# MDR32F8 register map
Vendor: Milandr; File version: 1.0
CPU: CM4 r1p1, little endian, no MPU, no FPU, 3 interrupt priority bits
Registers are 32-bit, read-write, reset 0x0 unless marked. A register's access mark holds for its fields unless they carry their own. Offsets are from the block's base; [hi:lo] are bit positions; {n}, {i} and the like mark numbered series; 'fields as' and 'values as' point back to an identical list.

## MDR_SPW — SPW controller
Base 0x40088000
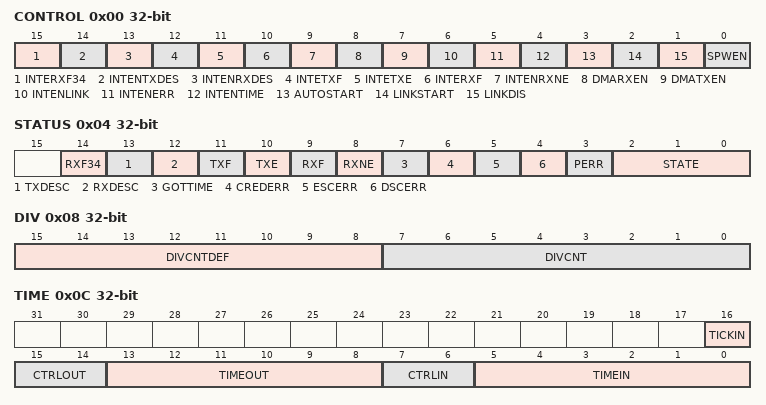
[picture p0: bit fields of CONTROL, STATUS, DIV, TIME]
0x00 CONTROL — SPW Control Register
  [15] INTERXF34, [14] INTENTXDES, [13] INTENRXDES, [12] INTETXF, [11] INTETXE, [10] INTERXF, [9] INTENRXNE, [8] DMARXEN, [7] DMATXEN, [6] INTENLINK, [5] INTENERR, [4] INTENTIME, [3] AUTOSTART, [2] LINKSTART, [1] LINKDIS, [0] SPWEN
0x04 STATUS — SPW Status Register
  [14] RXF34, [13] TXDESC, [12] RXDESC, [11] TXF, [10] TXE, [9] RXF, [8] RXNE, [7] GOTTIME, [6] CREDERR, [5] ESCERR, [4] DSCERR, [3] PERR, [2:0] STATE
0x08 DIV — DIV Configuration Register
  [15:8] DIVCNTDEF, [7:0] DIVCNT
0x0C TIME
  [16] TICKIN, [15:14] CTRLOUT, [13:8] TIMEOUT, [7:6] CTRLIN, [5:0] TIMEIN
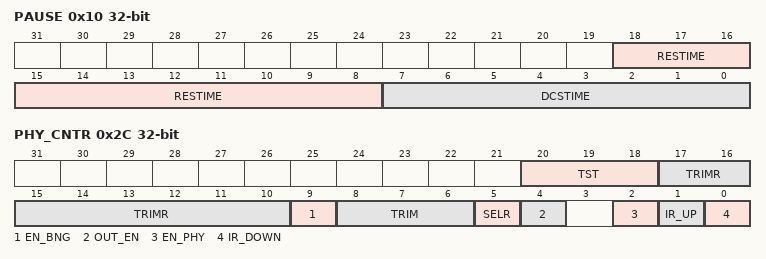
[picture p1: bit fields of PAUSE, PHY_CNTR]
0x10 PAUSE
  [18:8] RESTIME, [7:0] DCSTIME
0x14 FIFORX
  [31:0] DATA
0x18 FIFOTX
  [31:0] DATA
0x1C CNTRX_PACK
  [31:0] NOTNULLCNT
0x20 CNTRX0_PACK
  [31:0] NULLCNT
0x24 NUM_TXDESC
  [3:0] NEM_TXDESC
0x28 NUM_RXDESC
  [3:0] NUM_RXDESC
0x2C PHY_CNTR
  [20:18] TST, [17:10] TRIMR, [9] EN_BNG, [8:6] TRIM, [5] SELR, [4] OUT_EN, [2] EN_PHY, [1] IR_UP, [0] IR_DOWN
{0x40+4i} RXDESC{i} (i=0..15)
  [31:0] RXDES
{0x80+4i} TXDESC{i} (i=0..15)
  [31:0] TXDES

## TIMER0
Base 0x4008A000
Same registers: TIMER1 0x4008B000, TIMER2 0x4008C000, TIMER3 0x4008D000
0x00 CNT — Timer Counter Register
0x04 PSG — Timer Clock Prescaler Register
0x08 ARR — Timer Auto-Reload Register
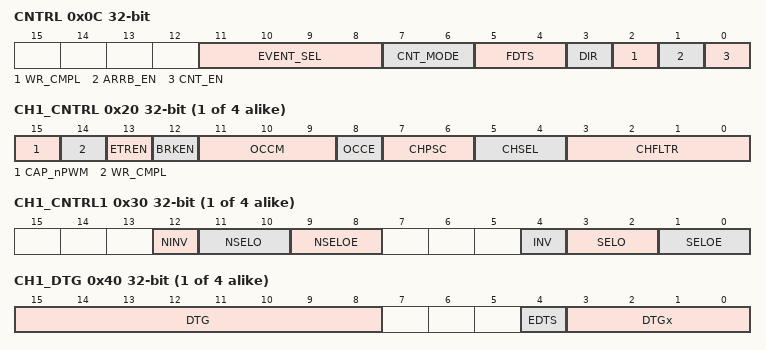
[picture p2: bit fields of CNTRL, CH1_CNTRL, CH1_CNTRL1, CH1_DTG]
0x0C CNTRL — Timer Control Register
  [11:8] EVENT_SEL, [7:6] CNT_MODE, [5:4] FDTS, [3] DIR, [2] WR_CMPL, [1] ARRB_EN, [0] CNT_EN
{0xC+4i} CCR{i} (i=1..4) — Timer Capture/Compare Register
  [31:0] CCR
{0x1C+4i} CH{i}_CNTRL (i=1..4) — Timer Channel Control Register
  [15] CAP_nPWM, [14] WR_CMPL, [13] ETREN, [12] BRKEN, [11:9] OCCM, [8] OCCE, [7:6] CHPSC, [5:4] CHSEL, [3:0] CHFLTR
{0x2C+4i} CH{i}_CNTRL1 (i=1..4) — Timer Channel Control1 Register
  [12] NINV, [11:10] NSELO, [9:8] NSELOE, [4] INV, [3:2] SELO, [1:0] SELOE
{0x3C+4i} CH{i}_DTG (i=1..4) — Timer Channel DTG Register
  [15:8] DTG, [4] EDTS, [3:0] DTGx
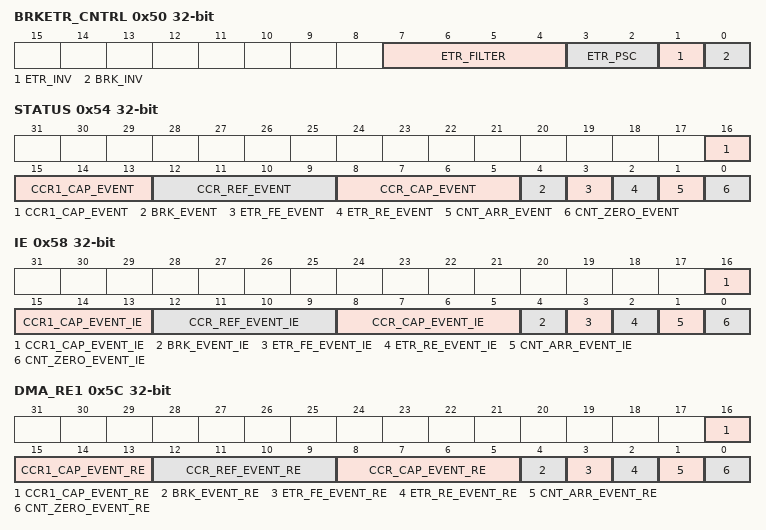
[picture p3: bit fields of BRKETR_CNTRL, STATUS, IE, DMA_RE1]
0x50 BRKETR_CNTRL — Timer BRK/ETR Control Register
  [7:4] ETR_FILTER, [3:2] ETR_PSC, [1] ETR_INV, [0] BRK_INV
0x54 STATUS — Timer Status Register
  [16:13] CCR1_CAP_EVENT, [12:9] CCR_REF_EVENT, [8:5] CCR_CAP_EVENT, [4] BRK_EVENT, [3] ETR_FE_EVENT, [2] ETR_RE_EVENT, [1] CNT_ARR_EVENT, [0] CNT_ZERO_EVENT
0x58 IE — Timer Interrupt Enable Register
  [16:13] CCR1_CAP_EVENT_IE, [12:9] CCR_REF_EVENT_IE, [8:5] CCR_CAP_EVENT_IE, [4] BRK_EVENT_IE, [3] ETR_FE_EVENT_IE, [2] ETR_RE_EVENT_IE, [1] CNT_ARR_EVENT_IE, [0] CNT_ZERO_EVENT_IE
0x5C DMA_RE1 — Timer DMA Request Enable Register
  [16:13] CCR1_CAP_EVENT_RE, [12:9] CCR_REF_EVENT_RE, [8:5] CCR_CAP_EVENT_RE, [4] BRK_EVENT_RE, [3] ETR_FE_EVENT_RE, [2] ETR_RE_EVENT_RE, [1] CNT_ARR_EVENT_RE, [0] CNT_ZERO_EVENT_RE
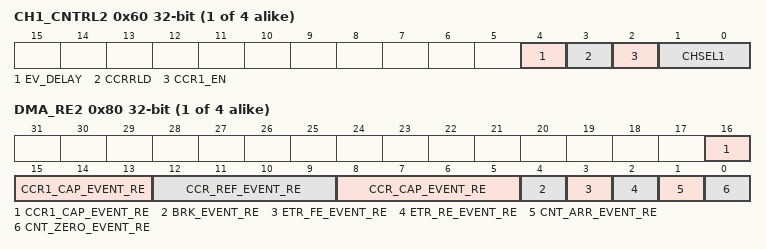
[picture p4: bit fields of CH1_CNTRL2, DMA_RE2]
{0x5C+4i} CH{i}_CNTRL2 (i=1..4) — Timer Channel Control2 Register
  [4] EV_DELAY, [3] CCRRLD, [2] CCR1_EN, [1:0] CHSEL1
0x70 CCR11 — Timer Capture/Compare1 Register
  [31:0] CCR1
0x74 CCR21 — Timer Capture/Compare1 Register
  [31:0] CCR1
0x78 CCR31 — Timer Capture/Compare1 Register
  [31:0] CCR1
0x7C CCR41 — Timer Capture/Compare1 Register
  [31:0] CCR1
{0x78+4i} DMA_RE{i} (i=2..5) — Timer DMA Request Enable Register
  fields as DMA_RE1

## MDR_CAN — CAN interfase controller registers
Base 0x40090000
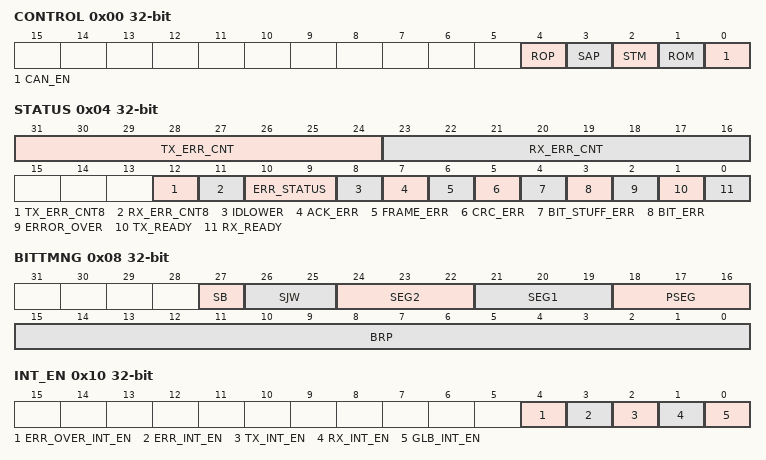
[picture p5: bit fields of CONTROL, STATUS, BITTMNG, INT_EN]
0x00 CONTROL — CAN Control Register
  [4] ROP, [3] SAP, [2] STM, [1] ROM, [0] CAN_EN
0x04 STATUS — CAN Status Register
  [31:24] TX_ERR_CNT ro, [23:16] RX_ERR_CNT ro, [12] TX_ERR_CNT8 ro, [11] RX_ERR_CNT8 ro, [10:9] ERR_STATUS ro, [8] IDLOWER, [7] ACK_ERR, [6] FRAME_ERR, [5] CRC_ERR, [4] BIT_STUFF_ERR, [3] BIT_ERR, [2] ERROR_OVER, [1] TX_READY ro, [0] RX_READY ro
0x08 BITTMNG — CAN Bittiming Register
  [27] SB, [26:25] SJW, [24:22] SEG2, [21:19] SEG1, [18:16] PSEG, [15:0] BRP
0x10 INT_EN — CAN Interrupt enable Register
  [4] ERR_OVER_INT_EN, [3] ERR_INT_EN, [2] TX_INT_EN, [1] RX_INT_EN, [0] GLB_INT_EN
0x1C OVER
  [7:0] ERROR_MAX
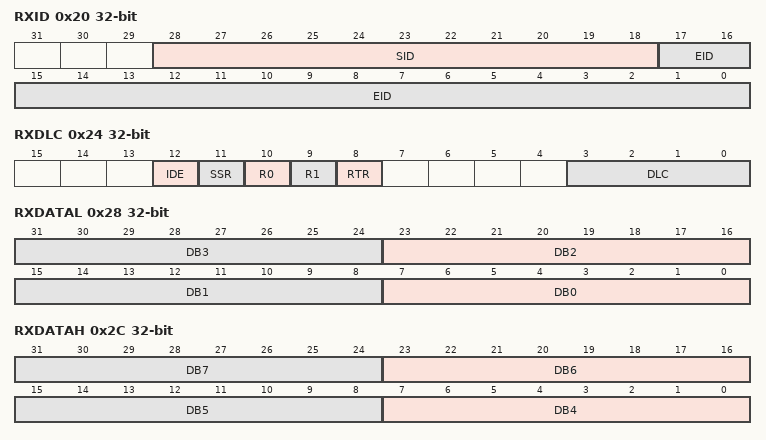
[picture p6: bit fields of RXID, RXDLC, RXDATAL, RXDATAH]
0x20 RXID — CAN Receive ID Register
  [28:18] SID, [17:0] EID
0x24 RXDLC — CAN Receive DLC Register
  [12] IDE, [11] SSR, [10] R0, [9] R1, [8] RTR, [3:0] DLC
0x28 RXDATAL — CAN Receive Data low Register
  [8n+7:8n] DB{n} (n=0..3)
0x2C RXDATAH — CAN Receive Data high Register
  [8n-25:8n-32] DB{n} (n=4..7)
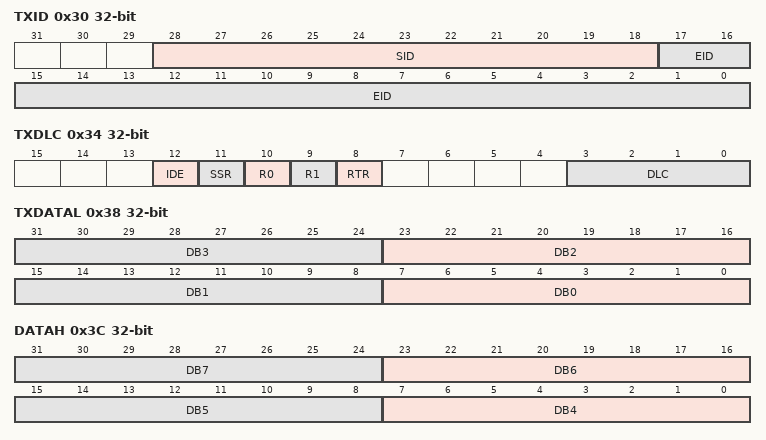
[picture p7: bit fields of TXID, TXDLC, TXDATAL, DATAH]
0x30 TXID — CAN Transmit ID Register
  [28:18] SID, [17:0] EID
0x34 TXDLC — CAN Transmit DLC Register
  [12] IDE, [11] SSR, [10] R0, [9] R1, [8] RTR, [3:0] DLC
0x38 TXDATAL — CAN Transmit Data low Register
  [8n+7:8n] DB{n} (n=0..3)
0x3C DATAH — CAN Transmit Data high Register
  [8n-25:8n-32] DB{n} (n=4..7)
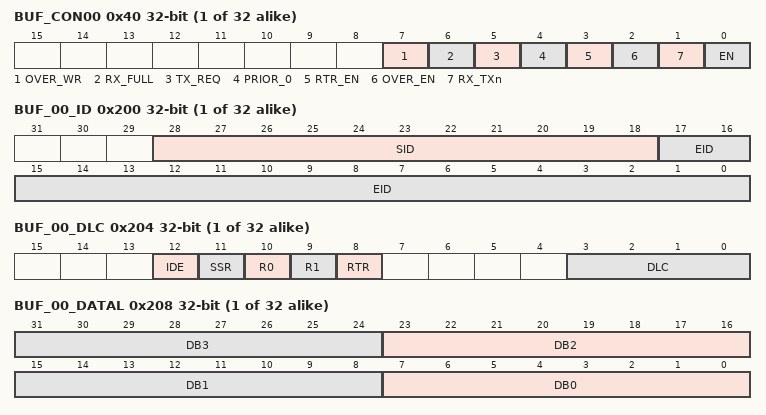
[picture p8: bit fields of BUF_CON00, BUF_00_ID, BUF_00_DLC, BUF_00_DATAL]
{0x40+4i} BUF_CON{i:02} (i=0..31) — CAN Buffer Connection Register
  [7] OVER_WR, [6] RX_FULL, [5] TX_REQ, [4] PRIOR_0, [3] RTR_EN, [2] OVER_EN, [1] RX_TXn, [0] EN
0xC0 INT_RX
  [31:0] CAN_INT_RX
0xC4 RX
  [31:0] CAN_RX
0xC8 INT_TX
  [31:0] CAN_INT_TX
0xCC TX
  [31:0] CAN_TX
{0x200+0x10*i} BUF_{i:02}_ID (i=0..31) — CAN Buffer ID Register
  [28:18] SID, [17:0] EID
{0x204+0x10*i} BUF_{i:02}_DLC (i=0..31) — CAN Buffer DLC Register
  [12] IDE, [11] SSR, [10] R0, [9] R1, [8] RTR, [3:0] DLC
{0x208+0x10*i} BUF_{i:02}_DATAL (i=0..31) — CAN Buffer Data low Register
  [8n+7:8n] DB{n} (n=0..3)
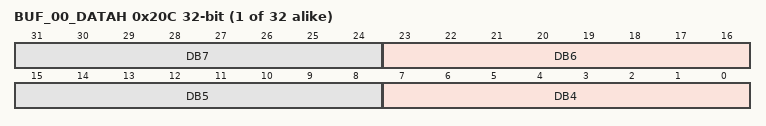
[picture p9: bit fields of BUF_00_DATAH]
{0x20C+0x10*i} BUF_{i:02}_DATAH (i=0..31) — CAN Buffer Data high Register
  [8n-25:8n-32] DB{n} (n=4..7)
{0x500+8i} BUF_FILTER{i:02}_MASK (i=0..31)
{0x504+8i} BUF_FILTER{i:02}_FILTER (i=0..31)
